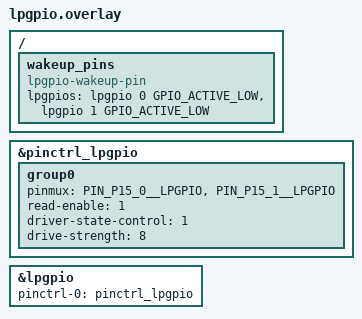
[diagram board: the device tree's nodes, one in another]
/* Copyright (C) Alif Semiconductor - All Rights Reserved.
 * Use, distribution and modification of this code is permitted under the
 * terms stated in the Alif Semiconductor Software License Agreement
 *
 * You should have received a copy of the Alif Semiconductor Software
 * License Agreement with this file. If not, please write to:
 * contact@alifsemi.com, or visit: https://alifsemi.com/license
 */

#include <dt-bindings/gpio/gpio.h>

&pinctrl_lpgpio {
	group0 {
		pinmux = <PIN_P15_0__LPGPIO>,
			 <PIN_P15_1__LPGPIO>;
		read-enable = <1>;
		driver-state-control = <1>;
		drive-strength = <8>;
	};
};

&lpgpio {
	pinctrl-0 = < &pinctrl_lpgpio >;
	pinctrl-names = "default";
	status = "okay";
};

/ {
	wakeup_pins: wakeup_pins {
		compatible = "lpgpio-wakeup-pin";
		lpgpios = <&lpgpio 0 GPIO_ACTIVE_LOW>,
			  <&lpgpio 1 GPIO_ACTIVE_LOW>;
	};
};
